# ioat91sam3s2 register map
Registers from a debugger description file.
Registers are 32-bit, access not given, no defined reset value unless marked. A register's access mark holds for its fields unless they carry their own. Addresses are absolute; registers are grouped by the start of their names; lines under a group give offsets from that group; [hi:lo] are bit positions; {n}, {i} and the like mark numbered series; 'fields as' and 'values as' point back to an identical list; <NAME> marks a mode.

## HSMCI
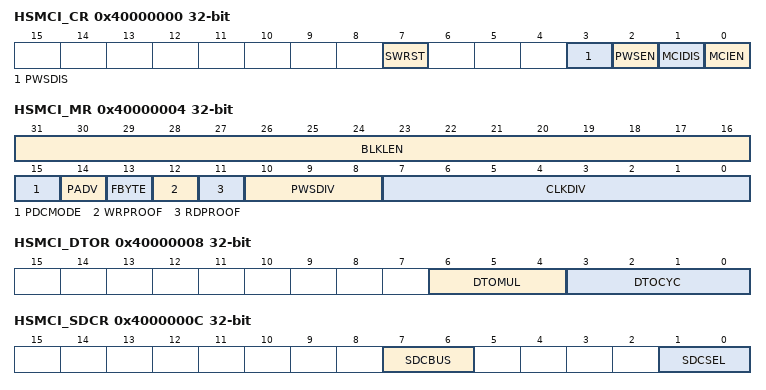
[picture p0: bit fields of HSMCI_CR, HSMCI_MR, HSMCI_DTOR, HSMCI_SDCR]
0x40000000 HSMCI_CR
  [7] SWRST, [3] PWSDIS, [2] PWSEN, [1] MCIDIS, [0] MCIEN
0x40000004 HSMCI_MR
  [31:16] BLKLEN, [15] PDCMODE, [14] PADV, [13] FBYTE, [12] WRPROOF, [11] RDPROOF, [10:8] PWSDIV, [7:0] CLKDIV
0x40000008 HSMCI_DTOR
  [6:4] DTOMUL, [3:0] DTOCYC
0x4000000C HSMCI_SDCR
  [7:6] SDCBUS, [1:0] SDCSEL
0x40000010 HSMCI_ARGR
  [31:0] ARG
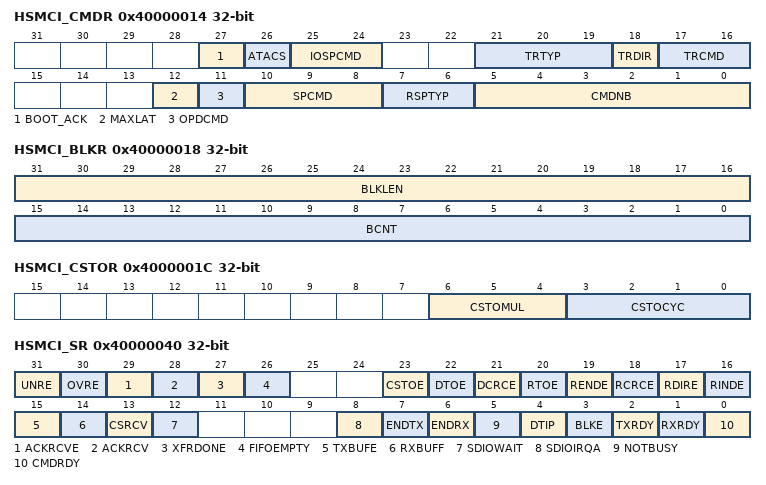
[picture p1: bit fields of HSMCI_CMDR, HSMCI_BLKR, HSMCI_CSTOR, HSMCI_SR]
0x40000014 HSMCI_CMDR
  [27] BOOT_ACK, [26] ATACS, [25:24] IOSPCMD, [21:19] TRTYP, [18] TRDIR, [17:16] TRCMD, [12] MAXLAT, [11] OPDCMD, [10:8] SPCMD, [7:6] RSPTYP, [5:0] CMDNB
0x40000018 HSMCI_BLKR
  [31:16] BLKLEN, [15:0] BCNT
0x4000001C HSMCI_CSTOR
  [6:4] CSTOMUL, [3:0] CSTOCYC
0x40000020 HSMCI_RSPR_{i} (i=0..3)
  [31:0] RSP
0x40000030 HSMCI_RDR
  [31:0] DATA
0x40000034 HSMCI_TDR
  [31:0] DATA
0x40000040 HSMCI_SR
  [31] UNRE, [30] OVRE, [29] ACKRCVE, [28] ACKRCV, [27] XFRDONE, [26] FIFOEMPTY, [23] CSTOE, [22] DTOE, [21] DCRCE, [20] RTOE, [19] RENDE, [18] RCRCE, [17] RDIRE, [16] RINDE, [15] TXBUFE, [14] RXBUFF, [13] CSRCV, [12] SDIOWAIT, [8] SDIOIRQA, [7] ENDTX, [6] ENDRX, [5] NOTBUSY, [4] DTIP, [3] BLKE, [2] TXRDY, [1] RXRDY, [0] CMDRDY
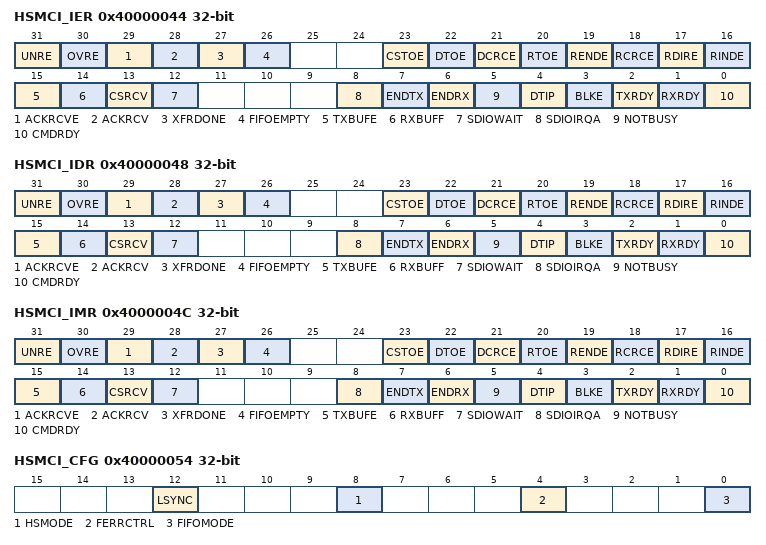
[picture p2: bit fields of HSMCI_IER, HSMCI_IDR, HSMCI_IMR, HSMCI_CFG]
0x40000044 HSMCI_IER
  fields as HSMCI_SR
0x40000048 HSMCI_IDR
  fields as HSMCI_SR
0x4000004C HSMCI_IMR
  fields as HSMCI_SR
0x40000054 HSMCI_CFG
  [12] LSYNC, [8] HSMODE, [4] FERRCTRL, [0] FIFOMODE
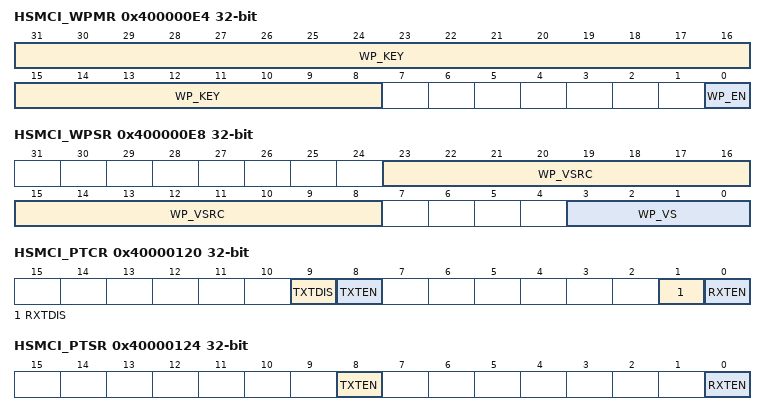
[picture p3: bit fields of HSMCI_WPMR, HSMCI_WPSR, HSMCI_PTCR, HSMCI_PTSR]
0x400000E4 HSMCI_WPMR
  [31:8] WP_KEY, [0] WP_EN
0x400000E8 HSMCI_WPSR
  [23:8] WP_VSRC, [3:0] WP_VS
0x40000100 HSMCI_RPR
  [31:0] RXPTR
0x40000104 HSMCI_RCR
  [15:0] RXCTR
0x40000108 HSMCI_TPR
  [31:0] TXPTR
0x4000010C HSMCI_TCR
  [15:0] TXCTR
0x40000110 HSMCI_RNPR
  [31:0] RXNPTR
0x40000114 HSMCI_RNCR
  [15:0] RXNCTR
0x40000118 HSMCI_TNPR
  [31:0] TXNPTR
0x4000011C HSMCI_TNCR
  [15:0] TXNCTR
0x40000120 HSMCI_PTCR
  [9] TXTDIS, [8] TXTEN, [1] RXTDIS, [0] RXTEN
0x40000124 HSMCI_PTSR
  [8] TXTEN, [0] RXTEN

## SSC
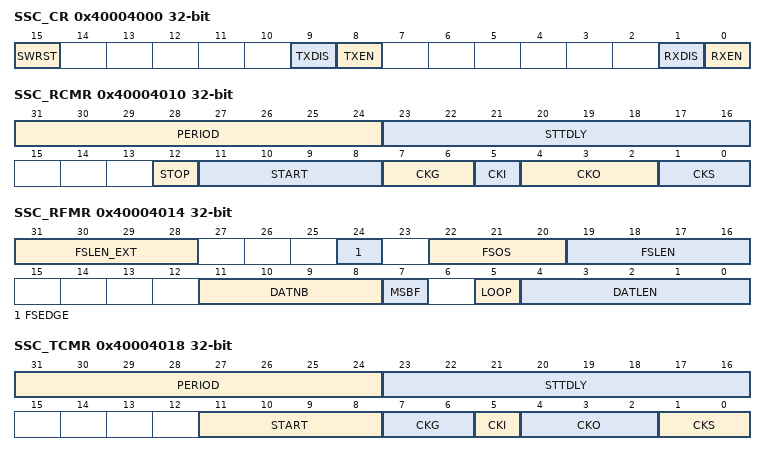
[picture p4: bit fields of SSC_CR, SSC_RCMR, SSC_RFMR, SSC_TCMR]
0x40004000 SSC_CR
  [15] SWRST, [9] TXDIS, [8] TXEN, [1] RXDIS, [0] RXEN
0x40004004 SSC_CMR
  [11:0] DIV
0x40004010 SSC_RCMR
  [31:24] PERIOD, [23:16] STTDLY, [12] STOP, [11:8] START, [7:6] CKG, [5] CKI, [4:2] CKO, [1:0] CKS
0x40004014 SSC_RFMR
  [31:28] FSLEN_EXT, [24] FSEDGE, [22:20] FSOS, [19:16] FSLEN, [11:8] DATNB, [7] MSBF, [5] LOOP, [4:0] DATLEN
0x40004018 SSC_TCMR
  [31:24] PERIOD, [23:16] STTDLY, [11:8] START, [7:6] CKG, [5] CKI, [4:2] CKO, [1:0] CKS
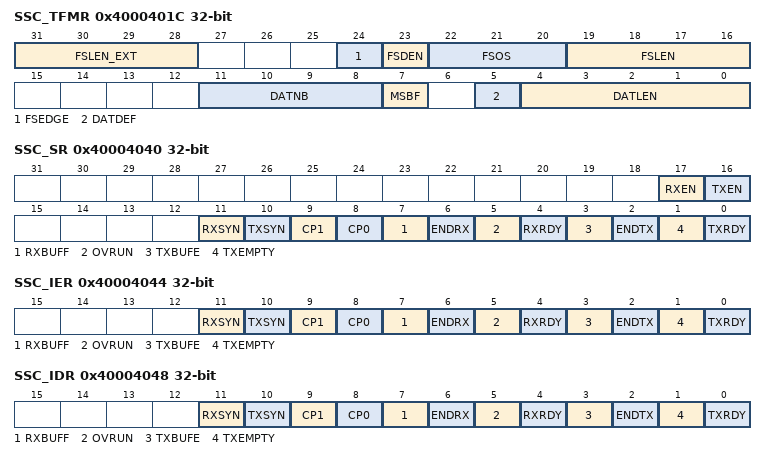
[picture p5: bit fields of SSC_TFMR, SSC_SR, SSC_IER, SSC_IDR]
0x4000401C SSC_TFMR
  [31:28] FSLEN_EXT, [24] FSEDGE, [23] FSDEN, [22:20] FSOS, [19:16] FSLEN, [11:8] DATNB, [7] MSBF, [5] DATDEF, [4:0] DATLEN
0x40004020 SSC_RHR
  [31:0] RDAT
0x40004024 SSC_THR
  [31:0] TDAT
0x40004030 SSC_RSHR
  [15:0] RSDAT
0x40004034 SSC_TSHR
  [15:0] TSDAT
0x40004038 SSC_RC0R
  [15:0] CP0
0x4000403C SSC_RC1R
  [15:0] CP1
0x40004040 SSC_SR
  [17] RXEN, [16] TXEN, [11] RXSYN, [10] TXSYN, [9] CP1, [8] CP0, [7] RXBUFF, [6] ENDRX, [5] OVRUN, [4] RXRDY, [3] TXBUFE, [2] ENDTX, [1] TXEMPTY, [0] TXRDY
0x40004044 SSC_IER
  [11] RXSYN, [10] TXSYN, [9] CP1, [8] CP0, [7] RXBUFF, [6] ENDRX, [5] OVRUN, [4] RXRDY, [3] TXBUFE, [2] ENDTX, [1] TXEMPTY, [0] TXRDY
0x40004048 SSC_IDR
  fields as SSC_IER
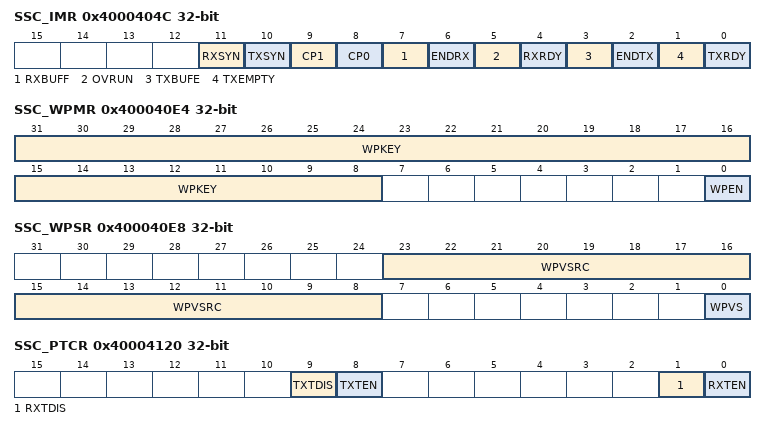
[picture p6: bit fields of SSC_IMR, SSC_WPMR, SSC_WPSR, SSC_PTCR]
0x4000404C SSC_IMR
  fields as SSC_IER
0x400040E4 SSC_WPMR
  [31:8] WPKEY, [0] WPEN
0x400040E8 SSC_WPSR
  [23:8] WPVSRC, [0] WPVS
0x40004100 SSC_RPR
  [31:0] RXPTR
0x40004104 SSC_RCR
  [15:0] RXCTR
0x40004108 SSC_TPR
  [31:0] TXPTR
0x4000410C SSC_TCR
  [15:0] TXCTR
0x40004110 SSC_RNPR
  [31:0] RXNPTR
0x40004114 SSC_RNCR
  [15:0] RXNCTR
0x40004118 SSC_TNPR
  [31:0] TXNPTR
0x4000411C SSC_TNCR
  [15:0] TXNCTR
0x40004120 SSC_PTCR
  [9] TXTDIS, [8] TXTEN, [1] RXTDIS, [0] RXTEN
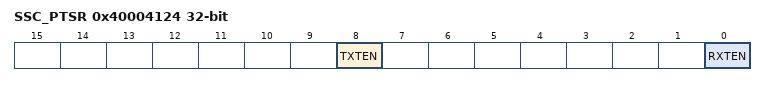
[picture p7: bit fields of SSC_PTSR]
0x40004124 SSC_PTSR
  [8] TXTEN, [0] RXTEN

## Notices in the file
Copyright (c) 2009, Atmel Corporation
All rights reserved.
Redistribution and use in source and binary forms, with or without
modification, are permitted provided that the following condition is met:
- Redistributions of source code must retain the above copyright notice,
this list of conditions and the disclaimer below.
Atmel's name may not be used to endorse or promote products derived from
this software without specific prior written permission.
DISCLAIMER:  THIS SOFTWARE IS PROVIDED BY ATMEL "AS IS" AND ANY EXPRESS OR
IMPLIED WARRANTIES, INCLUDING, BUT NOT LIMITED TO, THE IMPLIED WARRANTIES OF
MERCHANTABILITY, FITNESS FOR A PARTICULAR PURPOSE AND NON-INFRINGEMENT ARE
DISCLAIMED. IN NO EVENT SHALL ATMEL BE LIABLE FOR ANY DIRECT, INDIRECT,
INCIDENTAL, SPECIAL, EXEMPLARY, OR CONSEQUENTIAL DAMAGES (INCLUDING, BUT NOT
LIMITED TO, PROCUREMENT OF SUBSTITUTE GOODS OR SERVICES; LOSS OF USE, DATA,
OR PROFITS; OR BUSINESS INTERRUPTION) HOWEVER CAUSED AND ON ANY THEORY OF
LIABILITY, WHETHER IN CONTRACT, STRICT LIABILITY, OR TORT (INCLUDING
NEGLIGENCE OR OTHERWISE) ARISING IN ANY WAY OUT OF THE USE OF THIS SOFTWARE,
EVEN IF ADVISED OF THE POSSIBILITY OF SUCH DAMAGE.
